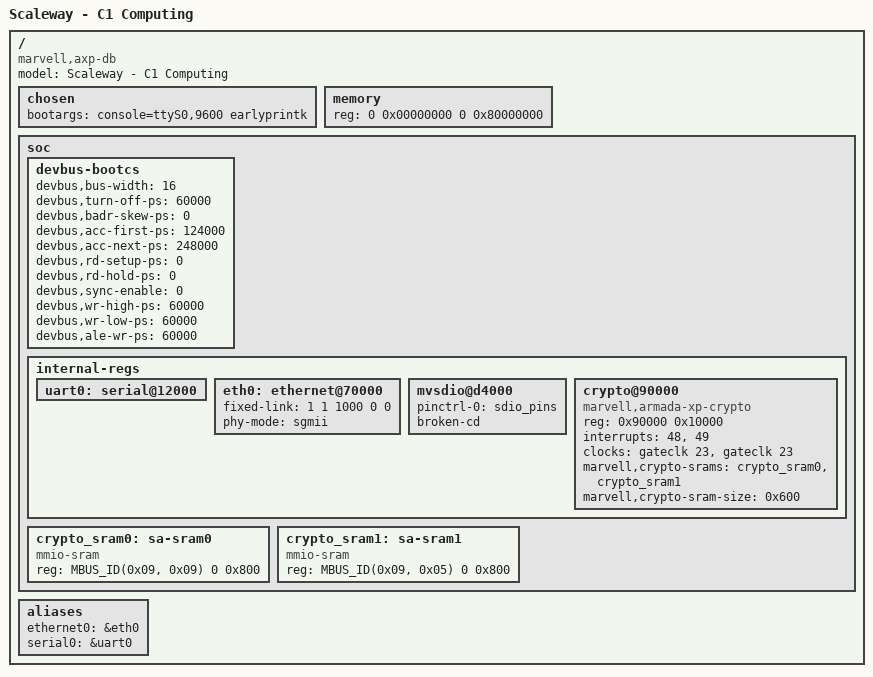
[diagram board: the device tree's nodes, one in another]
/*
 * Device Tree file for Online-Labs C1 Computing
 *
 * Copyright (C) 2012-2014 Marvell
 * Copyright (C) 2014-2015 Scaleway
 *
 * Lior Amsalem <alior@marvell.com>
 * Gregory CLEMENT <gregory.clement@free-electrons.com>
 * Thomas Petazzoni <thomas.petazzoni@free-electrons.com>
 * Manfred Touron <mtouron@ocs.online.net>
 * Vincent Auclair <vauclair@online.net>
 *
 * This file is licensed under the terms of the GNU General Public
 * License version 2.  This program is licensed "as is" without any
 * warranty of any kind, whether express or implied.
 */

/dts-v1/;
#include "armada-xp-mv78460.dtsi"

/ {
	model = "Scaleway - C1 Computing";
	compatible = "marvell,axp-db", "marvell,armadaxp-mv78460", "marvell,armadaxp", "marvell,armada-370-xp";

	chosen {
		bootargs = "console=ttyS0,9600 earlyprintk";
	};

	memory {
		device_type = "memory";
		reg = <0 0x00000000 0 0x80000000>; /* 2 GB */
	};

	soc {
		ranges = <MBUS_ID(0xf0, 0x01) 0 0 0xd0000000 0x100000
			  MBUS_ID(0x01, 0x1d) 0 0 0xfff00000 0x100000
			  MBUS_ID(0x01, 0x2f) 0 0 0xf0000000 0x1000000>;

		devbus-bootcs {
			status = "okay";

			/* Device Bus parameters are required */

			/* Read parameters */
			devbus,bus-width    = <16>;
			devbus,turn-off-ps  = <60000>;
			devbus,badr-skew-ps = <0>;
			devbus,acc-first-ps = <124000>;
			devbus,acc-next-ps  = <248000>;
			devbus,rd-setup-ps  = <0>;
			devbus,rd-hold-ps   = <0>;

			/* Write parameters */
			devbus,sync-enable = <0>;
			devbus,wr-high-ps  = <60000>;
			devbus,wr-low-ps   = <60000>;
			devbus,ale-wr-ps   = <60000>;

		};

		internal-regs {
			uart0: serial@12000 {
				status = "okay";
			};

			eth0: ethernet@70000 {
				status = "okay";
				fixed-link = <1 1 1000 0 0>;
				phy-mode = "sgmii";
			};

			mvsdio@d4000 {
				pinctrl-0 = <&sdio_pins>;
				pinctrl-names = "default";
				status = "okay";
				/* No CD or WP GPIOs */
				broken-cd;
			};

			crypto@90000 {
				compatible = "marvell,armada-xp-crypto";
				reg = <0x90000 0x10000>;
				reg-names = "regs";
				interrupts = <48>, <49>;
				clocks = <&gateclk 23>, <&gateclk 23>;
				clock-names = "cesa0", "cesa1";
				marvell,crypto-srams = <&crypto_sram0>, <&crypto_sram1>;
				marvell,crypto-sram-size = <0x600>;
				status = "okay";
			};
		};

		crypto_sram0: sa-sram0 {
			compatible = "mmio-sram";
			reg = <MBUS_ID(0x09, 0x09) 0 0x800>;
			#address-cells = <1>;
			#size-cells = <1>;
			ranges = <0 MBUS_ID(0x09, 0x09) 0 0x800>;
			status = "okay";
		};

		crypto_sram1: sa-sram1 {
			compatible = "mmio-sram";
			reg = <MBUS_ID(0x09, 0x05) 0 0x800>;
			#address-cells = <1>;
			#size-cells = <1>;
			ranges = <0 MBUS_ID(0x09, 0x05) 0 0x800>;
			status = "okay";
		};
	};
	aliases {
		ethernet0 = &eth0;
		serial0 = &uart0;
	};
};
